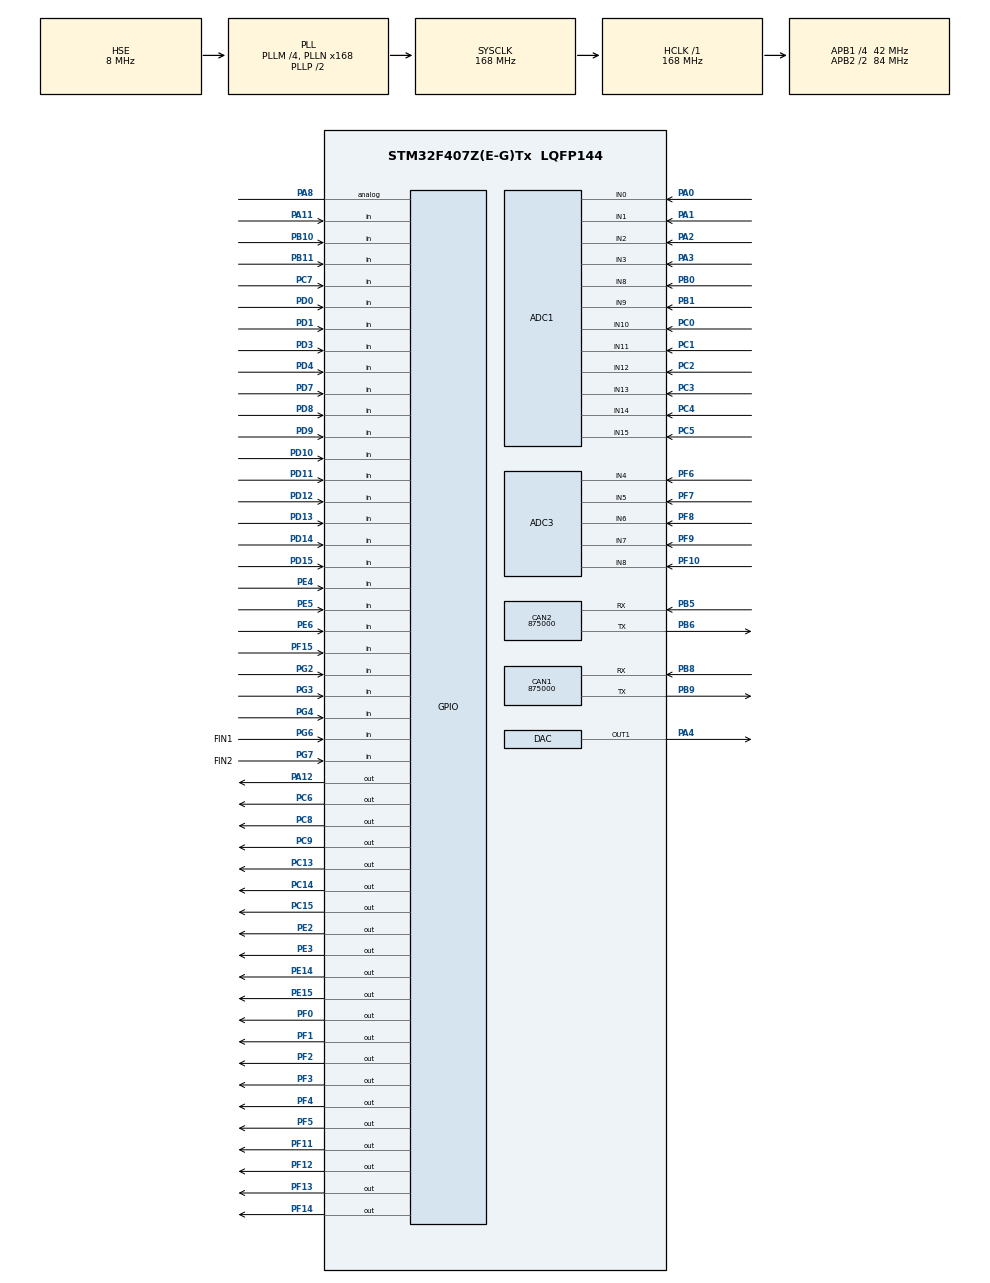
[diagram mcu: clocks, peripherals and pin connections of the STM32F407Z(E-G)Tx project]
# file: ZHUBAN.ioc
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ADC1.Channel-0\#ChannelRegularConversion=ADC_CHANNEL_0
ADC1.ClockPrescaler=ADC_CLOCK_SYNC_PCLK_DIV4
ADC1.NbrOfConversionFlag=1
ADC1.Rank-0\#ChannelRegularConversion=1
ADC1.SamplingTime-0\#ChannelRegularConversion=ADC_SAMPLETIME_3CYCLES
ADC1.master=1
ADC3.Channel-0\#ChannelRegularConversion=ADC_CHANNEL_4
ADC3.ClockPrescaler=ADC_CLOCK_SYNC_PCLK_DIV4
ADC3.NbrOfConversionFlag=1
ADC3.Rank-0\#ChannelRegularConversion=1
ADC3.SamplingTime-0\#ChannelRegularConversion=ADC_SAMPLETIME_3CYCLES
CAN1.CalculateBaudRate=875000
CAN1.CalculateTimeBit=1142
CAN1.CalculateTimeQuantum=380.95238095238096
CAN2.CalculateBaudRate=875000
CAN2.CalculateTimeBit=1142
CAN2.CalculateTimeQuantum=380.95238095238096
Mcu.Family=STM32F4
Mcu.Name=STM32F407Z(E-G)Tx
Mcu.Package=LQFP144
NVIC.PriorityGroup=NVIC_PRIORITYGROUP_4
PA0-WKUP.Signal=ADCx_IN0
PA1.Signal=ADCx_IN1
PA10.Signal=USART1_RX
PA11.Signal=GPIO_Input
PA12.Signal=GPIO_Output
PA13.Mode=Serial_Wire
PA13.Signal=SYS_JTMS-SWDIO
PA14.Mode=Serial_Wire
PA14.Signal=SYS_JTCK-SWCLK
PA2.Signal=ADCx_IN2
PA3.Signal=ADCx_IN3
PA4.Signal=COMP_DAC1_group
PA5.Signal=SPI1_SCK
PA6.Signal=SPI1_MISO
PA7.Signal=SPI1_MOSI
PA8.Signal=GPIO_Analog
PA9.Signal=USART1_TX
PB0.Signal=ADCx_IN8
PB1.Signal=ADCx_IN9
PB10.Signal=GPIO_Input
PB11.Signal=GPIO_Input
PB12.Signal=SPI2_NSS
PB13.Signal=SPI2_SCK
PB14.Signal=SPI2_MISO
PB15.Signal=SPI2_MOSI
PB5.Mode=CAN_Activate
PB5.Signal=CAN2_RX
PB6.Mode=CAN_Activate
PB6.Signal=CAN2_TX
PB8.Mode=CAN_Activate
PB8.Signal=CAN1_RX
PB9.Mode=CAN_Activate
PB9.Signal=CAN1_TX
PC0.Signal=ADCx_IN10
PC1.Signal=ADCx_IN11
PC10.Signal=UART4_TX
PC11.Signal=UART4_RX
PC12.Signal=UART5_TX
PC13-ANTI_TAMP.Signal=GPIO_Output
PC14-OSC32_IN.Signal=GPIO_Output
PC15-OSC32_OUT.Signal=GPIO_Output
PC2.Signal=ADCx_IN12
PC3.Signal=ADCx_IN13
PC4.Signal=ADCx_IN14
PC5.Signal=ADCx_IN15
PC6.Signal=GPIO_Output
PC7.Signal=GPIO_Input
PC8.Signal=GPIO_Output
PC9.Signal=GPIO_Output
PD0.Signal=GPIO_Input
PD1.Signal=GPIO_Input
PD10.Signal=GPIO_Input
PD11.Signal=GPIO_Input
PD12.Signal=GPIO_Input
PD13.Signal=GPIO_Input
PD14.Signal=GPIO_Input
PD15.Signal=GPIO_Input
PD2.Signal=UART5_RX
PD3.Signal=GPIO_Input
PD4.Signal=GPIO_Input
PD5.Signal=USART2_TX
PD6.Signal=USART2_RX
PD7.Signal=GPIO_Input
PD8.Signal=GPIO_Input
PD9.Signal=GPIO_Input
PE10.Signal=TIM1_CH2N
PE11.Signal=S_TIM1_CH2
PE12.Signal=TIM1_CH3N
PE13.Signal=S_TIM1_CH3
PE14.Signal=GPIO_Output
PE15.Signal=GPIO_Output
PE2.Signal=GPIO_Output
PE3.Signal=GPIO_Output
PE4.Signal=GPIO_Input
PE5.Signal=GPIO_Input
PE6.Signal=GPIO_Input
PE7.Signal=S_TIM1_ETR
PE8.Signal=TIM1_CH1N
PE9.Signal=S_TIM1_CH1
PF0.Signal=GPIO_Output
PF1.Signal=GPIO_Output
PF10.Mode=IN8
PF10.Signal=ADC3_IN8
PF11.Signal=GPIO_Output
PF12.Signal=GPIO_Output
PF13.Signal=GPIO_Output
PF14.Signal=GPIO_Output
PF15.Signal=GPIO_Input
PF2.Signal=GPIO_Output
PF3.Signal=GPIO_Output
PF4.Signal=GPIO_Output
PF5.Signal=GPIO_Output
PF6.Mode=IN4
PF6.Signal=ADC3_IN4
PF7.Mode=IN5
PF7.Signal=ADC3_IN5
PF8.Mode=IN6
PF8.Signal=ADC3_IN6
PF9.Mode=IN7
PF9.Signal=ADC3_IN7
PG2.Signal=GPIO_Input
PG3.Signal=GPIO_Input
PG4.Signal=GPIO_Input
PG6.GPIO_Label=FIN1
PG6.Signal=GPIO_Input
PG7.GPIO_Label=FIN2
PG7.Signal=GPIO_Input
PH0-OSC_IN.Mode=HSE-External-Oscillator
PH0-OSC_IN.Signal=RCC_OSC_IN
PH1-OSC_OUT.Mode=HSE-External-Oscillator
PH1-OSC_OUT.Signal=RCC_OSC_OUT
ProjectManager.HeapSize=0x200
ProjectManager.StackSize=0x400
ProjectManager.TargetToolchain=MDK-ARM V5.32
RCC.48MHZClocksFreq_Value=84000000
RCC.AHBFreq_Value=168000000
RCC.APB1CLKDivider=RCC_HCLK_DIV4
RCC.APB1Freq_Value=42000000
RCC.APB1TimFreq_Value=84000000
RCC.APB2CLKDivider=RCC_HCLK_DIV2
RCC.APB2Freq_Value=84000000
RCC.APB2TimFreq_Value=168000000
RCC.CortexFreq_Value=168000000
RCC.HCLKFreq_Value=168000000
RCC.HSE_VALUE=8000000
RCC.HSI_VALUE=16000000
RCC.LSE_VALUE=32768
RCC.PLLM=4
RCC.PLLN=168
RCC.PLLSourceVirtual=RCC_PLLSOURCE_HSE
RCC.SYSCLKFreq_VALUE=168000000
RCC.SYSCLKSource=RCC_SYSCLKSOURCE_PLLCLK
RCC.VCOOutputFreq_Value=336000000
SH.ADCx_IN0.0=ADC1_IN0,IN0
SH.ADCx_IN1.0=ADC1_IN1,IN1
SH.ADCx_IN10.0=ADC1_IN10,IN10
SH.ADCx_IN11.0=ADC1_IN11,IN11
SH.ADCx_IN12.0=ADC1_IN12,IN12
SH.ADCx_IN13.0=ADC1_IN13,IN13
SH.ADCx_IN14.0=ADC1_IN14,IN14
SH.ADCx_IN15.0=ADC1_IN15,IN15
SH.ADCx_IN2.0=ADC1_IN2,IN2
SH.ADCx_IN3.0=ADC1_IN3,IN3
SH.ADCx_IN8.0=ADC1_IN8,IN8
SH.ADCx_IN9.0=ADC1_IN9,IN9
SH.COMP_DAC1_group.0=DAC_OUT1,DAC_OUT1
SH.S_TIM1_CH1.0=TIM1_CH1
SH.S_TIM1_CH2.0=TIM1_CH2
SH.S_TIM1_CH3.0=TIM1_CH3
SH.S_TIM1_ETR.0=TIM1_ETR
VP_TIM1_VS_ClockSourceINT.Mode=Internal
board=custom

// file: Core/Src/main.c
/* USER CODE BEGIN Header */
/**
  ******************************************************************************
  * @file           : main.c
  * @brief          : Main program body
  ******************************************************************************
  * @attention
  *
  * Copyright (c) 2024 STMicroelectronics.
  * All rights reserved.
  *
  * This software is licensed under terms that can be found in the LICENSE file
  * in the root directory of this software component.
  * If no LICENSE file comes with this software, it is provided AS-IS.
  *
  ******************************************************************************
  */
/* USER CODE END Header */
#include "main.h"
#include "adc.h"
#include "can.h"
#include "dac.h"
#include "tim.h"
#include "gpio.h"

void SystemClock_Config(void);

int main(void)
{

  /* MCU Configuration--------------------------------------------------------*/

  /* Reset of all peripherals, Initializes the Flash interface and the Systick. */
  HAL_Init();

  /* Configure the system clock */
  SystemClock_Config();

  /* Initialize all configured peripherals */
  MX_GPIO_Init();
  MX_ADC1_Init();
  MX_ADC3_Init();
  MX_CAN1_Init();
  MX_CAN2_Init();
  MX_DAC_Init();
  MX_TIM1_Init();
  /* USER CODE BEGIN 2 */
	//HAL_TIM_PWM_Start(&htim1,TIM_CHANNEL_1);
	HAL_TIMEx_PWMN_Start(&htim1,TIM_CHANNEL_1);
  /* USER CODE END 2 */

  /* Infinite loop */
  while (1)
  {

    /* USER CODE BEGIN 3 */
		HAL_GPIO_TogglePin(GPIOC,GPIO_PIN_6);
		HAL_Delay(500);
  }
  /* USER CODE END 3 */
}

void SystemClock_Config(void)
{
  RCC_OscInitTypeDef RCC_OscInitStruct = {0};
  RCC_ClkInitTypeDef RCC_ClkInitStruct = {0};

  /** Configure the main internal regulator output voltage
  */
  __HAL_RCC_PWR_CLK_ENABLE();
  __HAL_PWR_VOLTAGESCALING_CONFIG(PWR_REGULATOR_VOLTAGE_SCALE1);

  /** Initializes the RCC Oscillators according to the specified parameters
  * in the RCC_OscInitTypeDef structure.
  */
  RCC_OscInitStruct.OscillatorType = RCC_OSCILLATORTYPE_HSE;
  RCC_OscInitStruct.HSEState = RCC_HSE_ON;
  RCC_OscInitStruct.PLL.PLLState = RCC_PLL_ON;
  RCC_OscInitStruct.PLL.PLLSource = RCC_PLLSOURCE_HSE;
  RCC_OscInitStruct.PLL.PLLM = 4;
  RCC_OscInitStruct.PLL.PLLN = 168;
  RCC_OscInitStruct.PLL.PLLP = RCC_PLLP_DIV2;
  RCC_OscInitStruct.PLL.PLLQ = 4;
  if (HAL_RCC_OscConfig(&RCC_OscInitStruct) != HAL_OK)
  {
    Error_Handler();
  }

  /** Initializes the CPU, AHB and APB buses clocks
  */
  RCC_ClkInitStruct.ClockType = RCC_CLOCKTYPE_HCLK|RCC_CLOCKTYPE_SYSCLK
                              |RCC_CLOCKTYPE_PCLK1|RCC_CLOCKTYPE_PCLK2;
  RCC_ClkInitStruct.SYSCLKSource = RCC_SYSCLKSOURCE_PLLCLK;
  RCC_ClkInitStruct.AHBCLKDivider = RCC_SYSCLK_DIV1;
  RCC_ClkInitStruct.APB1CLKDivider = RCC_HCLK_DIV4;
  RCC_ClkInitStruct.APB2CLKDivider = RCC_HCLK_DIV2;

  if (HAL_RCC_ClockConfig(&RCC_ClkInitStruct, FLASH_LATENCY_5) != HAL_OK)
  {
    Error_Handler();
  }
}

void Error_Handler(void)
{
  __disable_irq();
  while (1)
  {
  }
}
